AUTOSAR XML (schema 4-2-1)
package /ComponentTypes
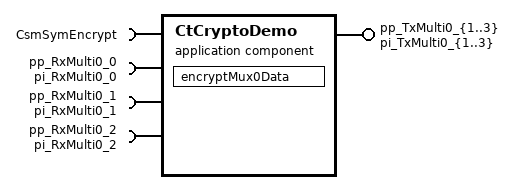
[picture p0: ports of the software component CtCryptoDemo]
  application sw component type CtCryptoDemo  # Demonstration of some cryptographic operations: - Receive data via Com - Encrypt received data - Transmit encryted data via Com
    provide port pp_TxMulti0_{1..3}: nonqueued-sender-com-spec{data-element=deTxMulti0_{1..3}, init-value={1..3}}, provided-interface=pi_TxMulti0_{1..3}
    4 x require port:
      CsmSymEncrypt: required-interface=CsmSymEncrypt
      pp_RxMulti0_0: nonqueued-receiver-com-spec{data-element=deRxMulti0_0, filter=data-filter-type=ALWAYS, init-value=1}, required-interface=pi_RxMulti0_0
      pp_RxMulti0_1: nonqueued-receiver-com-spec{data-element=deRxMulti0_1, filter=data-filter-type=ALWAYS, init-value=3}, required-interface=pi_RxMulti0_1
      pp_RxMulti0_2: nonqueued-receiver-com-spec{data-element=deRxMulti0_2, filter=data-filter-type=ALWAYS, init-value=0}, required-interface=pi_RxMulti0_2
    behavior CtCryptoDemo_InternalBehavior
      data received event DRT_encryptMux0Data_pi_RxMulti0_0_deRxMulti0_0: start-on-event=encryptMux0Data, data=pp_RxMulti0_0.deRxMulti0_0
      runnable encryptMux0Data
        data-receive-point-by-arguments:
          access REC_pi_RxMulti0_{0..2}_deRxMulti0_{0..2}: accessed-variable=pp_RxMulti0_{0..2}.deRxMulti0_{0..2}
        data-send-points:
          access SEND_pp_TxMulti0_{1..3}_deTxMulti0_{1..3}: accessed-variable=pp_TxMulti0_{1..3}.deTxMulti0_{1..3}
        sync call SC_CsmSymEncrypt_SymEncryptFinish: operation=CsmSymEncrypt.SymEncryptFinish, timeout=0
        sync call SC_CsmSymEncrypt_SymEncryptStart: operation=CsmSymEncrypt.SymEncryptStart, timeout=0
        sync call SC_CsmSymEncrypt_SymEncryptUpdate: operation=CsmSymEncrypt.SymEncryptUpdate, timeout=0
  swc implementation CtCryptoDemo_Implementation: behavior=CtCryptoDemo_InternalBehavior
    code-descriptors:
      code Default: artifact-descriptors=autosar-engineering-object={short-label=Default, category=SWSRC}
